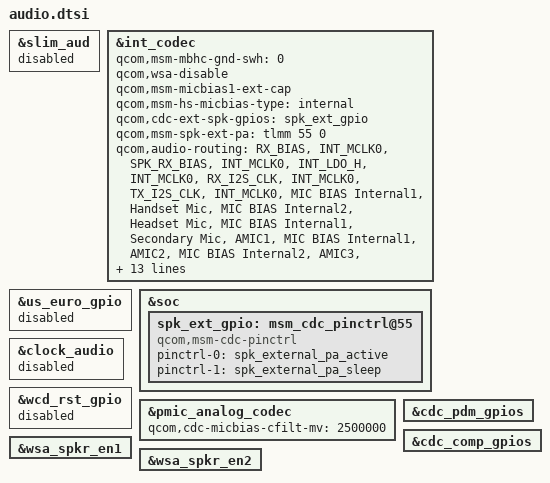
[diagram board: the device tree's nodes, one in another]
&slim_aud {
        status = "disabled";
};

&int_codec {
        status = "okay";  //nubia modify
		qcom,msm-mbhc-gnd-swh = <0>; //nubia modify
		qcom,wsa-disable;  //nubia modify
		qcom,msm-micbias1-ext-cap;
		/delete-property/ qcom,msm-micbias2-ext-cap;
		qcom,msm-hs-micbias-type = "internal";
		/delete-property/ qcom,us-euro-gpios;  //nubia modify
		/delete-property/ qcom,cdc-dmic-gpios; //nubia modify
		qcom,cdc-ext-spk-gpios = <&spk_ext_gpio>;
		qcom,msm-spk-ext-pa = <&tlmm 55 0>;
                qcom,audio-routing =
			"RX_BIAS", "INT_MCLK0",
			"SPK_RX_BIAS", "INT_MCLK0",
			"INT_LDO_H", "INT_MCLK0",
			"RX_I2S_CLK", "INT_MCLK0",
			"TX_I2S_CLK", "INT_MCLK0",
			"MIC BIAS Internal1", "Handset Mic",  //nubia modify
			"MIC BIAS Internal2", "Headset Mic",
			"MIC BIAS Internal1", "Secondary Mic",
			"AMIC1", "MIC BIAS Internal1",
			"AMIC2", "MIC BIAS Internal2",
			"AMIC3", "MIC BIAS Internal1",
			"DMIC1", "MIC BIAS External",
			"MIC BIAS External", "Digital Mic1",
			"DMIC2", "MIC BIAS External",
			"MIC BIAS External", "Digital Mic2",
			"DMIC3", "MIC BIAS External",
			"MIC BIAS External", "Digital Mic3",
			"DMIC4", "MIC BIAS External",
			"MIC BIAS External", "Digital Mic4",
			"SpkrLeft IN", "SPK1 OUT",
			"SpkrRight IN", "SPK2 OUT",
			"PDM_IN_RX1", "PDM_OUT_RX1",
			"PDM_IN_RX2", "PDM_OUT_RX2",
			"PDM_IN_RX3", "PDM_OUT_RX3",
			"ADC1_IN", "ADC1_OUT",
			"ADC2_IN", "ADC2_OUT",
			"ADC3_IN", "ADC3_OUT";
		qcom,wsa-max-devs = <0>; //nubia modify
};

&us_euro_gpio {
		status = "disable"; //nubia modify
};

&soc {
	spk_ext_gpio: msm_cdc_pinctrl@55 { //nubia modify
		compatible = "qcom,msm-cdc-pinctrl";
		pinctrl-names = "aud_active", "aud_sleep";
		pinctrl-0 = <&spk_external_pa_active>;
		pinctrl-1 = <&spk_external_pa_sleep>;
	};
};

&clock_audio {
		status = "disable"; //nubia modify
};

&wcd_rst_gpio {
		status = "disable"; //nubia modify
};

&pmic_analog_codec {
         status = "okay";  //nubia modify
         qcom,cdc-micbias-cfilt-mv = <2500000>;  //nubia modify 
};

&cdc_pdm_gpios {
         status = "okay";  //nubia modify
};

&cdc_comp_gpios {
         status = "okay";  //nubia modify
};

&wsa_spkr_en1 {
	      /delete-property/ pinctrl-names;
	      /delete-property/ pinctrl-0;
	      /delete-property/ pinctrl-1;
};

&wsa_spkr_en2 {
	      /delete-property/ pinctrl-names;
	      /delete-property/ pinctrl-0;
	      /delete-property/ pinctrl-1;
};
